# PRU_ICSSG0_IEP0 register map
Vendor: Texas Instruments
Peripheral module from a debugger description file (folder J7ES).
Registers are 32-bit, read-write, reset 0x0 unless marked. A register's access mark holds for its fields unless they carry their own. Offsets are as the file gives them; lines under a group give offsets from that group; [hi:lo] are bit positions; {n}, {i} and the like mark numbered series; 'fields as' and 'values as' point back to an identical list; <NAME> marks a mode.

## PRU_ICSSG0_IEP0
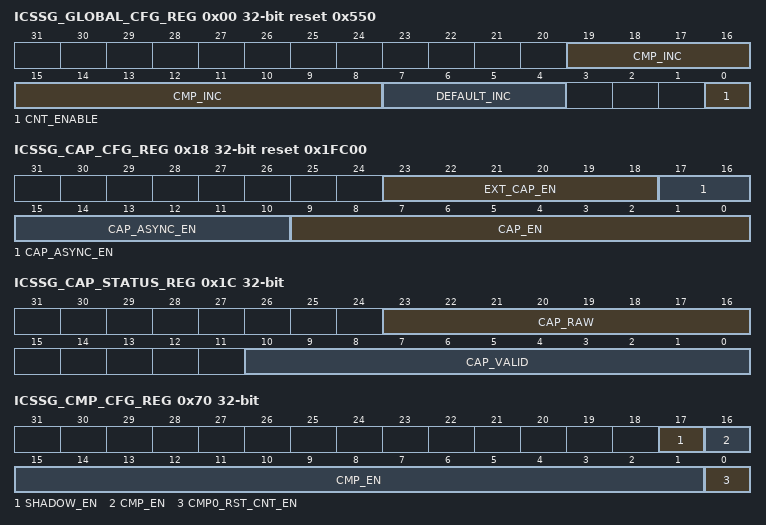
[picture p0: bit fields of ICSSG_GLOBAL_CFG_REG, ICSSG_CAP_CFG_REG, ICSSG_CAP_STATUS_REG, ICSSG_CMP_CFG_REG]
0x00 ICSSG_GLOBAL_CFG_REG reset 0x550 — Global Configuration Register.
  [19:8] CMP_INC — Defines the increment value when compensation is active
  [7:4] DEFAULT_INC — Defines the default increment value
  [0] CNT_ENABLE — Counter enable.
0x04 ICSSG_GLOBAL_STATUS_REG access not given — Status Register.
  [0] CNT_OVF — Counter overflow status. (access RW1C)
0x08 ICSSG_COMPEN_REG — Compensation Register.
  [22:0] COMPEN_CNT — 0h = Compensation is disabled counter inc by default_inc
0x0C ICSSG_SLOW_COMPEN_REG — Slow Compensation Register.
  [31:0] SLOW_COMPEN_CNT — Slow compensation counter.
0x10 ICSSG_COUNT_REG0 — 64-bit Count Value Low Register.
  [31:0] COUNT_LO — When Shadow Mode is disabled, this is the 64-bit count value (lower 32-bits). The count is incremented (DEFAULT_INC or CMP_INC) on every positive edge of ICSSGn_IEP_CLK (200MHz) or ICSSGn_ICLK. In 64-bit mode, reading this value locks the
0x14 ICSSG_COUNT_REG1 — 64-bit Count Value High Register.
  [31:0] COUNT_HI — When Shadow Mode is disabled:
0x18 ICSSG_CAP_CFG_REG reset 0x1FC00 — Capture Configuration Register.
  [23:18] EXT_CAP_EN
  [17:10] CAP_ASYNC_EN — Synchronization of the capture inputs to the ICSS_IEP_CLK/ ICSS_VCLK_CLK enable.
  [9:0] CAP_EN
0x1C ICSSG_CAP_STATUS_REG ro — Capture Status Register.
  [23:16] CAP_RAW — Raw/Current status bit for each of the capture registers, where CAP_RAW[n] maps to CAPR[n].
  [10:0] CAP_VALID — A Capture Valid Status , OR tree
0x20 ICSSG_CAPR0_REG0 ro — Capture Rise 0 Low Register.
  [31:0] CAPR0_0 — Value captured for CAPR&lt;i&gt; (fall) event, where i = 0 to 5. Lower 32-bits.
{0x24+8i} ICSSG_CAPR{i}_REG1 ro (i=0..5) — Capture Rise {i} High Register.
  [31:0] CAPR{i}_1 — Value captured for CAPR&lt;i&gt; (rise) event, where i = 0 to 5. Upper 32-bits.
0x28 ICSSG_CAPR1_REG0 ro — Capture Rise 1 Low Register.
  [31:0] CAPR1_0 — Value captured for CAPR&lt;i&gt; (fall) event, where i = 0 to 5. Lower 32-bits.
0x30 ICSSG_CAPR2_REG0 ro — Capture Rise 2 Low Register
  [31:0] CAPR2_0 — Value captured for CAPR&lt;i&gt; (fall) event, where i = 0 to 5. Lower 32-bits.
{0x20+8i} ICSSG_CAPR{i}_REG0 ro (i=3..5) — Capture Rise {i} Low Register.
  [31:0] CAPR{i}_0 — Value captured for CAPR&lt;i&gt; (fall) event, where i = 0 to 5. Lower 32-bits.
0x50 ICSSG_CAPR6_REG0 ro — Capture Rise 6 Low Register.
  [31:0] CAPR6_0 — Value captured for CAPR6 event. Lower 32-bits.
0x54 ICSSG_CAPR6_REG1 ro — Capture Rise 6 High Register.
  [31:0] CAPR6_1 — Value captured for CAPR6 event. Upper 32-bits.
0x58 ICSSG_CAPF6_REG0 ro — Capture Fall 6 Low Register.
  [31:0] CAPF6_0 — Value captured for CAPF6 (fall) event. Lower 32-bits.
0x5C ICSSG_CAPF6_REG1 ro — Capture Fall 6 High Register.
  [31:0] CAPF6_1 — Value captured for CAPF6 (fall) event. Lower 32-bits.
0x60 ICSSG_CAPR7_REG0 ro — Capture Rise 7 Low Register.
  [31:0] CAPR7_0 — Value captured for CAPR7 (rise) event. Lower 32-bits.
0x64 ICSSG_CAPR7_REG1 ro — Capture Rise 7 High Register.
  [31:0] CAPR7_1 — Value captured for CAPR7 (rise) event. Upper 32-bits.
0x68 ICSSG_CAPF7_REG0 ro — Capture Fall 7 Low Register.
  [31:0] CAPF7_0 — Value captured for CAPF7 (fall) event. Lower 32-bits.
0x6C ICSSG_CAPF7_REG1 ro — Capture Fall 7 High Register.
  [31:0] CAPF7_1 — Value captured for CAPF7 (fall) event. Upper 32-bits.
0x70 ICSSG_CMP_CFG_REG — Compare Configuration Register.
  [17] SHADOW_EN
  [16:1] CMP_EN — Enable bits for each of the compare registers
  [0] CMP0_RST_CNT_EN — Enable the reset of the counter
0x74 ICSSG_CMP_STATUS_REG access not given — Compare Status Register.
  [15:0] CMP_STATUS — Status bit for each of the compare registers. 'Match' indicates the current counter is greater than or equal to the compare value. Note it is the firmware's responsibility to handle the IEP overflow. (access RW1C)
{0x78+8i} ICSSG_CMP{i}_REG0 (i=0..7) — Compare {i} Low Register.
  [31:0] CMP{i}_0 — Compare {i} low value
{0x7C+8i} ICSSG_CMP{i}_REG1 (i=0..7) — Compare {i} High Register.
  [31:0] CMP{i}_1 — Compare {i} high value
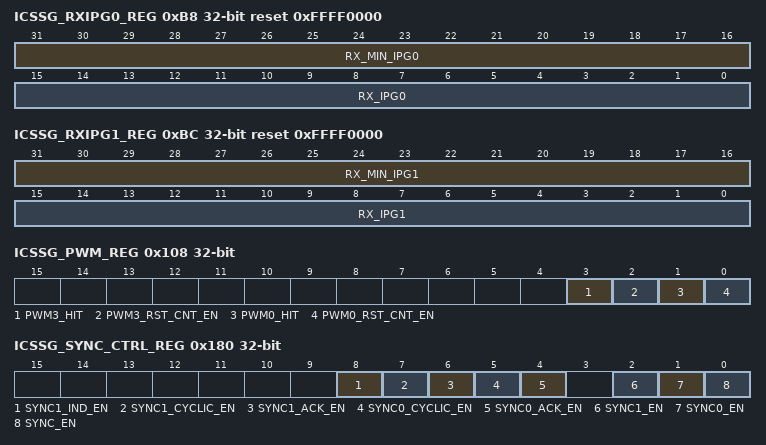
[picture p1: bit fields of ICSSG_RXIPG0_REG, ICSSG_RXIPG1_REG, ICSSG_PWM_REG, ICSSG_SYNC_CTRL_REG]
0xB8 ICSSG_RXIPG0_REG access per field reset 0xFFFF0000 — Status for the RX port which is attached to PRU0 Register.
  [31:16] RX_MIN_IPG0 rw — Defines the minimum number of ICSS_IEP_CLK/ICCS_VCLK_CLK cycles that is RX_DV is sampled low.
  [15:0] RX_IPG0 ro — Records the current number of ICSS_IEP_CLK/ICSS_VCLK_CLK cycles RX_DV is sampled low.
0xBC ICSSG_RXIPG1_REG access per field reset 0xFFFF0000 — Status for the RX port which is attached to PRU1 Register.
  [31:16] RX_MIN_IPG1 rw — Defines the minimum number of ICSS_IEP_CLK/ICSS_VCLK_CLK cycles that is RX_DV is sampled low.
  [15:0] RX_IPG1 ro — Records the current number of ICSS_IEP_CLK/ICSS_VCLK_CLK cycles RX_DV is sampled low.
{0x80+8i} ICSSG_CMP{i}_REG0 (i=8..15) — Compare {i} Low Register.
  [31:0] CMP{i}_0 — Compare {i} low value
0xC4 ICSSG_CMP8_REG1 — Compare 8 High Register.
  [31:0] CMP8_1 — Reset value (upper 32-bits). This register enables SW to define the reset state of the Master Counter, which can be reset by the following events (if enabled):
{0x84+8i} ICSSG_CMP{i}_REG1 (i=9..15) — Compare {i} High Register.
  [31:0] CMP{i}_1 — Compare {i} high value
0x100 ICSSG_COUNT_RESET_VAL_REG0 — Reset value of the Master Counter (lower 32-bits) Register.
  [31:0] RESET_VAL_0 — Reset value (lower 32-bits). This register enables SW to define the reset state of the Master Counter, which can be reset by the following events (if enabled):
0x104 ICSSG_COUNT_RESET_VAL_REG1 — Reset value of the Master Counter (upper 32-bits) Register.
  [31:0] RESET_VAL_1 — This enables SW to define the reset state of the Master counter when it gets reset do to the following 3 possible events if enabled: CMP0 event; eHRPWM0_SYNCO event; eHRPWM3_SYNCO event. It should be in increments of the DEFAULT_INC, default state is 5 For example, 0000_000Ah
0x108 ICSSG_PWM_REG access not given — PWM Sync Out Register.
  [3] PWM3_HIT — The raw status bit of eHRPWM3_SYNCO event. (access RW1C)
  [2] PWM3_RST_CNT_EN rw — Enable the reset of the counter by a eHRPWM3_SYNCO event.
  [1] PWM0_HIT — The raw status bit of eHRPWM0_SYNCO event. (access RW1C)
  [0] PWM0_RST_CNT_EN rw — Enable the reset of the counter by a eHRPWM0_SYNCO event.
{0x10C+8i} ICSSG_CAPR{i}_BI_REG0 ro (i=0..6) — Capture Big Indian Rise{i:02} Register.
  [31:0] CAPR{i}_0 — Capture Value for CAPR{i} event.
0x110 ICSSG_CAPR0_BI_REG1 ro — Capture Big Indian Rise10 Register.
  [31:0] CAPR0_1 — Capture Value for CAPR0 event.
0x118 ICSSG_CAPR1_BI_REG1 ro — Capture Big Indian Rise11 Register
  [31:0] CAPR1_1 — Capture Value for CAPR1 event.
{0x110+8i} ICSSG_CAPR{i}_BI_REG1 ro (i=2..6) — Capture Big Indian Rise{i+10} Register.
  [31:0] CAPR{i}_1 — Capture Value for CAPR{i} event.
0x144 ICSSG_CAPF6_BI_REG0 ro — Capture Big Indian Fall06 Register.
  [31:0] CAPF6_0 — Capture Value for CAPF6 event.
0x148 ICSSG_CAPF6_BI_REG1 ro — Capture Big Indian Fall16 Register.
  [31:0] CAPF6_1 — Capture Value for CAPF6 event.
0x14C ICSSG_CAPR7_BI_REG0 ro — Capture Big Indian Rise07 Register.
  [31:0] CAPR7_0 — Capture Value for CAPR7 event.
0x150 ICSSG_CAPR7_BI_REG1 ro — Capture Big Indian Rise17 Register.
  [31:0] CAPR7_1 — Capture Value for CAPR7 event.
0x154 ICSSG_CAPF7_BI_REG0 ro — Capture Big Indian Fall07 Register.
  [31:0] CAPF7_0 — Capture Value for CAPF7 event.
0x158 ICSSG_CAPF7_BI_REG1 ro — Capture Big Indian Fall17 Register.
  [31:0] CAPF7_1 — Capture Value for CAPF7 event.
0x180 ICSSG_SYNC_CTRL_REG — Sync Generation Control Register.
  [8] SYNC1_IND_EN — SYNC1 independent mode enable. Independent mode means the SYNC1 signal can be different from SYNC0.
  [7] SYNC1_CYCLIC_EN — SYNC1 single shot or cyclic/auto generation mode enable
  [6] SYNC1_ACK_EN — SYNC1 acknowledgement mode enable
  [5] SYNC0_CYCLIC_EN — SYNC0 single shot or cyclic/auto generation mode enable
  [4] SYNC0_ACK_EN — SYNC0 acknowledgement mode enable
  [2] SYNC1_EN — SYNC1 generation enable
  [1] SYNC0_EN — SYNC0 generation enable
  [0] SYNC_EN — SYNC generation enable
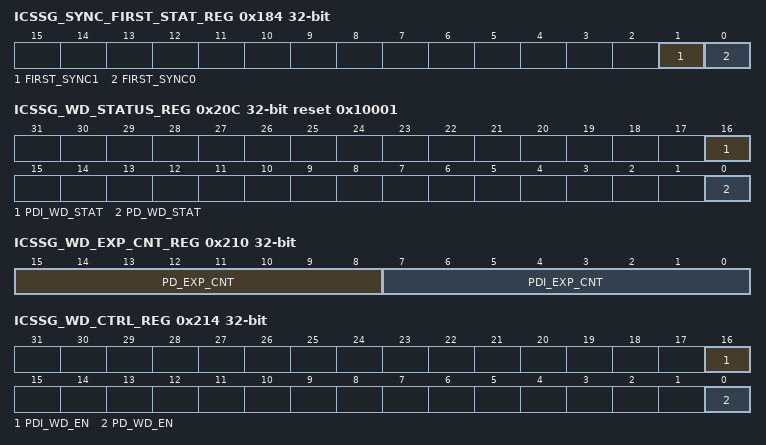
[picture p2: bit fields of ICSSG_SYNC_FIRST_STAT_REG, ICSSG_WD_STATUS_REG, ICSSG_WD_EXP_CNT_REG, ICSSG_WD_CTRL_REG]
0x184 ICSSG_SYNC_FIRST_STAT_REG ro — Sync Generation First Event Status Register.
  [1] FIRST_SYNC1 — SYNC1 First Event status
  [0] FIRST_SYNC0 — SYNC0 First Event status
0x188 ICSSG_SYNC0_STAT_REG ro — Sync 0 Status Register.
  [0] SYNC0_PEND — SYNC0 pending state
0x18C ICSSG_SYNC1_STAT_REG ro — Sync 1 Status Register.
  [0] SYNC1_PEND — SYNC1 pending state
0x190 ICSSG_SYNC_PWIDTH_REG — Sync Pulse Width Configure Register.
  [31:0] SYNC_HPW — Defines the number of clock cycles SYNC0/1 will be high.
0x194 ICSSG_SYNC0_PERIOD_REG reset 0x1 — Sync 0 Period Configure Register.
  [31:0] SYNC0_PERIOD — Defines the period between the rising edges of SYNC0.
0x198 ICSSG_SYNC1_DELAY_REG — Sync 1 Delay Register.
  [31:0] SYNC1_DELAY — When SYNC1_IND_EN = 0, defines number of clock cycles from the start of SYNC0 to the start of SYNC1.
0x19C ICSSG_SYNC_START_REG — Sync Start Configure Register.
  [31:0] SYNC_START — Defines the start time after the activation event.
0x200 ICSSG_WD_PREDIV_REG reset 0x4E20 — Watchdog Pre-Divider Register
  [15:0] PRE_DIV — Defines the number of ICSS_IEP_CLK cycles per WD clock event. Note that the WD clock is a free-running clock. The value 0x4e20 (or 20000) generates a rate of 100 us if ICSS_IEP_CLK is 200 MHz.
0x204 ICSSG_PDI_WD_TIM_REG reset 0x3E8 — PDI Watchdog Timer Configure Register.
  [15:0] PDI_WD_TIME — Defines the number of WD ticks (or increments) for PDI WD, that is, the number of WD increments. If PRUSS_IEP_WD_PREDIV[15-0] PRE_DIV is set to 100us, then the value 0x03e8 (or 1000) provides a rate of 100ms.
0x208 ICSSG_PD_WD_TIM_REG reset 0x3E8 — PD Watchdog Timer Configure Register.
  [15:0] PD_WD_TIME — Defines the number of WD ticks (or increments) for PD WD, that is, the number of WD increments.
0x20C ICSSG_WD_STATUS_REG ro reset 0x10001 — Watchdog Status Register.
  [16] PDI_WD_STAT — WD PDI status.
  [0] PD_WD_STAT — WD PD status (triggered by Sync Mangers status).
0x210 ICSSG_WD_EXP_CNT_REG — Watchdog Timer Expiration Counter Register.
  [15:8] PD_EXP_CNT — WD PD expiration counter. Counter increments on every PD time out and stops at FFh.
  [7:0] PDI_EXP_CNT — WD PDI expiration counter. Counter increments on every PDI time out and stops at FFh.
0x214 ICSSG_WD_CTRL_REG — Watchdog Control Register.
  [16] PDI_WD_EN — Watchdog PDI
  [0] PD_WD_EN — Watchdog PD
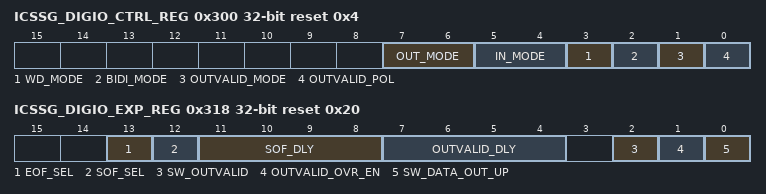
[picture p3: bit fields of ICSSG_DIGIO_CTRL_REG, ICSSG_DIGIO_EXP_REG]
0x300 ICSSG_DIGIO_CTRL_REG access per field reset 0x4 — DIGIO Control Register.
  [7:6] OUT_MODE rw — Defines events that triggers data out to be updated.
  [5:4] IN_MODE rw — Defines event that triggers data in to be sampled
  [3] WD_MODE rw — Defines Watchdog behavior
  [2] BIDI_MODE ro — Defines the digital input/output direction. NOTE THAT DUE TO INTEGRATION, ACTUAL MODE IS UNIDIRECTIONAL IN THIS DEVICE.
  [1] OUTVALID_MODE rw — Defines the outvalid mode behavior.
  [0] OUTVALID_POL ro — Defines OUTVALID polarity
0x304 ICSSG_DIGIO_STATUS_REG ro — DIGIO Status Register.
  [31:0] DIGIO_STAT — Reserved
0x308 ICSSG_DIGIO_DATA_IN_REG ro — DIGIO Data Input Register.
  [31:0] DATA_IN — Data input. Digital inputs can be configured to be sampled in four ways.
0x30C ICSSG_DIGIO_DATA_IN_RAW_REG ro — DIGIO Data Input Direct Sample Register.
  [31:0] DATA_IN_RAW — Data input which direct sample of PR&lt;k&gt;_EDIO_DATA[0:31]. Only PR&lt;k&gt;_EDIO_DATA[0:3] are exported to device pins in this device.
0x310 ICSSG_DIGIO_DATA_OUT_REG — DIGIO Data Output Register.
  [31:0] DATA_OUT — Data output. Digital outputs can be configured to be updated in four ways.
0x314 ICSSG_DIGIO_DATA_OUT_EN_REG — DIGIO Data Input which controls tri-state of pr<k>_edio_data_out_en[3:0] Register.
  [31:0] DATA_OUT_EN — Data input which controls tri-state of PR&lt;k&gt;_EDIO_DATA[0:3]
0x318 ICSSG_DIGIO_EXP_REG reset 0x20 — DIGIO, Defines which RX_EOF is used Register.
  [13] EOF_SEL — Defines which RX_EOF is used for PR&lt;k&gt;_EDIO_DATA_IN[0:3] capture
  [12] SOF_SEL — Defines which RX_SOF is used for PR&lt;k&gt;_EDIO_DATA_IN[0:3] capture
  [11:8] SOF_DLY — Define the number of iep_clk (ICSS_IEP_CLK) cycle delay of SOF PR&lt;k&gt;_EDIO_DATA_IN[0:3] capture
  [7:4] OUTVALID_DLY — Define the number of iep_clk (ICSS_IEP_CLK) cycle delay on assertion of PR&lt;k&gt;_EDIO_OUTVALID. Min is 2 clock cycles. Max is 16 clock cycles
  [2] SW_OUTVALID — PR&lt;k&gt;_EDIO_OUTVALID = SW_OUTVALID, only if OUTVALID_OVR_EN is set.
  [1] OUTVALID_OVR_EN — Software override enable
  [0] SW_DATA_OUT_UP — Defines the value of pr&lt;k&gt;_edio_data_out when OUTVALID_OVR_EN = 1.
